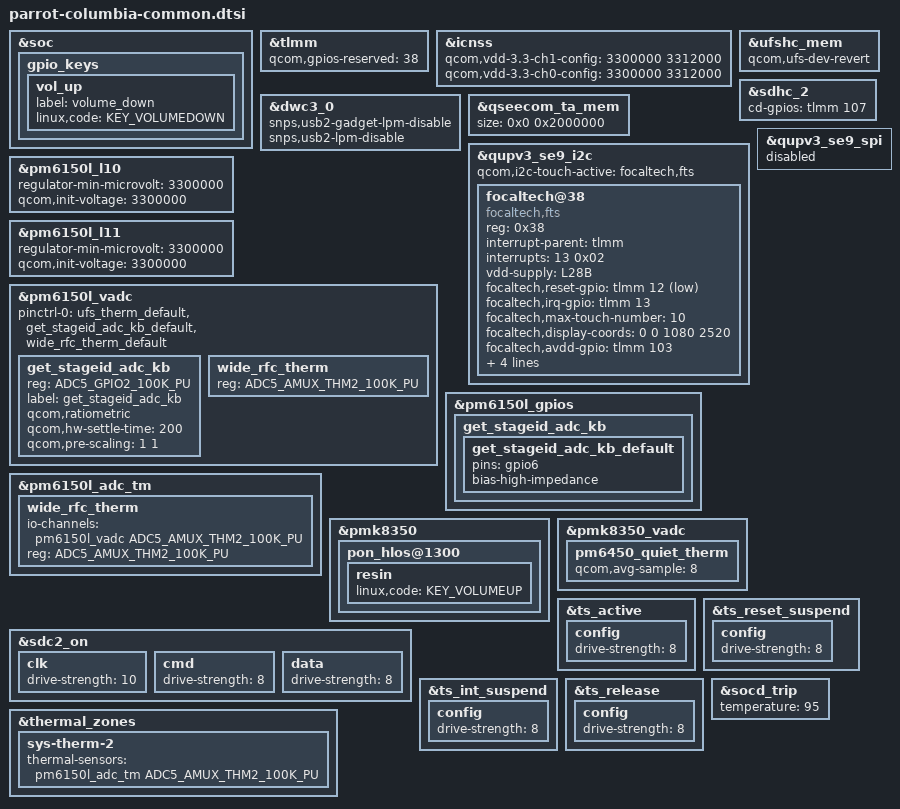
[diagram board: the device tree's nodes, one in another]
&soc {
	gpio_keys {
		vol_up {
			label = "volume_down";
			linux,code = <KEY_VOLUMEDOWN>;
		};
	};
};

&tlmm {
	qcom,gpios-reserved = <38>;
};

&icnss {
	qcom,vdd-3.3-ch1-config = <3300000 3312000>;
	qcom,vdd-3.3-ch0-config = <3300000 3312000>;
};

&dwc3_0 {
	snps,usb2-gadget-lpm-disable;
	snps,usb2-lpm-disable;
};

&ufshc_mem {
	qcom,ufs-dev-revert;
};

&sdhc_2 {
	cd-gpios = <&tlmm 107 GPIO_ACTIVE_HIGH>;

	/delete-property/ no-sdio;
	/delete-property/ no-mmc;
};

&qseecom_ta_mem {
	size = <0x0 0x2000000>;
};

&qupv3_se9_i2c {
	#address-cells = <1>;
	#size-cells = <0>;
	qcom,i2c-touch-active = "focaltech,fts";
	status = "okay";

	focaltech@38 {
		compatible = "focaltech,fts";
		reg = <0x38>;
		interrupt-parent = <&tlmm>;
		interrupts = <13 0x02>;
		vdd-supply = <&L28B>;
		focaltech,reset-gpio = <&tlmm 12 0x01>;
		focaltech,irq-gpio = <&tlmm 13 0x02>;
		focaltech,max-touch-number = <10>;
		focaltech,display-coords =  <0 0 1080 2520>;
		focaltech,avdd-gpio = <&tlmm 103 0x0>;
		pinctrl-names = "pmx_ts_active", "pmx_ts_suspend", "pmx_ts_release";
		pinctrl-0 = <&ts_active>;
		pinctrl-1 = <&ts_int_suspend &ts_reset_suspend>;
		pinctrl-2 = <&ts_release>;

		panel = <&dsi_samsung_amoled_cmd>;
	};
};

&qupv3_se9_spi {
	status = "disabled";
};

&pm6150l_l10 {
	regulator-min-microvolt = <3300000>;
	qcom,init-voltage = <3300000>;
};

&pm6150l_l11 {
	regulator-min-microvolt = <3300000>;
	qcom,init-voltage = <3300000>;
};

&pm6150l_vadc {
	pinctrl-0 = <&ufs_therm_default &get_stageid_adc_kb_default &wide_rfc_therm_default>;

	get_stageid_adc_kb {
		reg = <ADC5_GPIO2_100K_PU>;
		label = "get_stageid_adc_kb";
		qcom,ratiometric;
		qcom,hw-settle-time = <200>;
		qcom,pre-scaling = <1 1>;
	};

	wide_rfc_therm {
		reg = <ADC5_AMUX_THM2_100K_PU>;
	};
};

&pm6150l_gpios {
	get_stageid_adc_kb {
		get_stageid_adc_kb_default: get_stageid_adc_kb_default {
			pins = "gpio6";
			bias-high-impedance;
		};
	};
};

&pm6150l_adc_tm {
	wide_rfc_therm {
		io-channels = <&pm6150l_vadc ADC5_AMUX_THM2_100K_PU>;
		reg = <ADC5_AMUX_THM2_100K_PU>;
	};
};

&pmk8350 {
	pon_hlos@1300 {
		resin {
			linux,code = <KEY_VOLUMEUP>;
		};
	};
};

&pmk8350_vadc {
	pm6450_quiet_therm {
		qcom,avg-sample = <8>;
	};
};

&sdc2_on {
	clk {
		drive-strength = <10>;
	};

	cmd {
		drive-strength = <8>;
	};

	data {
		drive-strength = <8>;
	};
};

&ts_active {
	config {
		drive-strength = <8>;
	};
};

&ts_reset_suspend {
	config {
		drive-strength = <8>;
	};
};

&ts_int_suspend {
	config {
		drive-strength = <8>;
	};
};

&ts_release {
	config {
		drive-strength = <8>;
	};
};

&thermal_zones {
	sys-therm-2 {
		thermal-sensors = <&pm6150l_adc_tm ADC5_AMUX_THM2_100K_PU>;
	};
};

&socd_trip {
	temperature = <95>;
};
